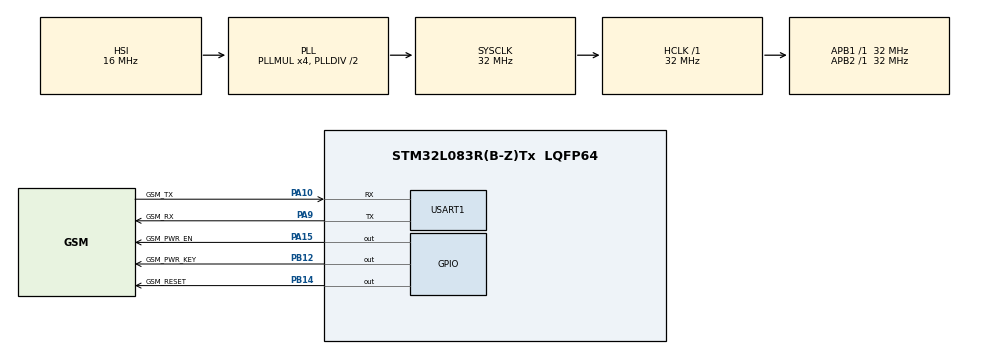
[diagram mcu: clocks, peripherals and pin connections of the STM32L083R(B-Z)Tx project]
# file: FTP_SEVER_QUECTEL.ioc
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Mcu.Family=STM32L0
Mcu.Name=STM32L083R(B-Z)Tx
Mcu.Package=LQFP64
NVIC.USART1_IRQn=true\:0\:0\:false\:false\:true\:true\:true
PA10.GPIO_Label=GSM_TX
PA10.Mode=Asynchronous
PA10.Signal=USART1_RX
PA13.Mode=Serial_Wire
PA13.Signal=SYS_SWDIO
PA14.Mode=Serial_Wire
PA14.Signal=SYS_SWCLK
PA15.GPIO_Label=GSM_PWR_EN
PA15.Signal=GPIO_Output
PA9.GPIO_Label=GSM_RX
PA9.Mode=Asynchronous
PA9.Signal=USART1_TX
PB12.GPIO_Label=GSM_PWR_KEY
PB12.Signal=GPIO_Output
PB14.GPIO_Label=GSM_RESET
PB14.Signal=GPIO_Output
ProjectManager.HeapSize=0x200
ProjectManager.StackSize=0x400
ProjectManager.TargetToolchain=MDK-ARM V5
RCC.AHBFreq_Value=32000000
RCC.APB1Freq_Value=32000000
RCC.APB1TimFreq_Value=32000000
RCC.APB2Freq_Value=32000000
RCC.APB2TimFreq_Value=32000000
RCC.HCLKFreq_Value=32000000
RCC.HSE_VALUE=8000000
RCC.HSI16_VALUE=16000000
RCC.HSI48_VALUE=48000000
RCC.HSI_VALUE=16000000
RCC.LSE_VALUE=32768
RCC.MSI_VALUE=2097000
RCC.PLLMUL=RCC_PLLMUL_4
RCC.SYSCLKFreq_VALUE=32000000
RCC.SYSCLKSource=RCC_SYSCLKSOURCE_PLLCLK
RCC.VCOOutputFreq_Value=64000000
USART1.VirtualMode-Asynchronous=VM_ASYNC
board=custom

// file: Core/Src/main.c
/* USER CODE BEGIN Header */
/**
  ******************************************************************************
  * @file           : main.c
  * @brief          : Main program body
  ******************************************************************************
  * @attention
  *
  * Copyright (c) 2022 STMicroelectronics.
  * All rights reserved.
  *
  * This software is licensed under terms that can be found in the LICENSE file
  * in the root directory of this software component.
  * If no LICENSE file comes with this software, it is provided AS-IS.
  *
  ******************************************************************************
  */
/* USER CODE END Header */
#include "main.h"

/* USER CODE BEGIN Includes */
#include "app_debug.h"
#include "ringBuffer.h"
#include "hw_polling_task.h"
#include "gsm_data_layer.h"
/* USER CODE END Includes */

UART_HandleTypeDef huart1;

void SystemClock_Config(void);
static void MX_GPIO_Init(void);
static void MX_USART1_UART_Init(void);
/* USER CODE BEGIN PFP */

void gsm_handler (void);

//void getDone (at_cmd_response_evt_t evt);   // du lieu nhan ve
/**************   main handle program  ******************/

/* USER CODE END PFP */

int main(void)
{

  /* MCU Configuration--------------------------------------------------------*/

  /* Reset of all peripherals, Initializes the Flash interface and the Systick. */
  HAL_Init();

  /* Configure the system clock */
  SystemClock_Config();

  /* Initialize all configured peripherals */
  MX_GPIO_Init();
  MX_USART1_UART_Init();
  /* USER CODE BEGIN 2 */
    HAL_Delay (300);
    ringBufferInit (&ringBuff, temp);        // seting for ring buffer
    USART1 ->CR1 |=   1 << 5;               /// RXEN ENABLE
  /* USER CODE END 2 */

  /* Infinite loop */
  /* USER CODE BEGIN WHILE */
  while (1)
  {
      gsm_handler();
    /* USER CODE END WHILE */

  }
}

void SystemClock_Config(void)
{
  RCC_OscInitTypeDef RCC_OscInitStruct = {0};
  RCC_ClkInitTypeDef RCC_ClkInitStruct = {0};
  RCC_PeriphCLKInitTypeDef PeriphClkInit = {0};

  /** Configure the main internal regulator output voltage
  */
  __HAL_PWR_VOLTAGESCALING_CONFIG(PWR_REGULATOR_VOLTAGE_SCALE1);
  /** Initializes the RCC Oscillators according to the specified parameters
  * in the RCC_OscInitTypeDef structure.
  */
  RCC_OscInitStruct.OscillatorType = RCC_OSCILLATORTYPE_HSI;
  RCC_OscInitStruct.HSIState = RCC_HSI_ON;
  RCC_OscInitStruct.HSICalibrationValue = RCC_HSICALIBRATION_DEFAULT;
  RCC_OscInitStruct.PLL.PLLState = RCC_PLL_ON;
  RCC_OscInitStruct.PLL.PLLSource = RCC_PLLSOURCE_HSI;
  RCC_OscInitStruct.PLL.PLLMUL = RCC_PLLMUL_4;
  RCC_OscInitStruct.PLL.PLLDIV = RCC_PLLDIV_2;
  if (HAL_RCC_OscConfig(&RCC_OscInitStruct) != HAL_OK)
  {
    Error_Handler();
  }
  /** Initializes the CPU, AHB and APB buses clocks
  */
  RCC_ClkInitStruct.ClockType = RCC_CLOCKTYPE_HCLK|RCC_CLOCKTYPE_SYSCLK
                              |RCC_CLOCKTYPE_PCLK1|RCC_CLOCKTYPE_PCLK2;
  RCC_ClkInitStruct.SYSCLKSource = RCC_SYSCLKSOURCE_PLLCLK;
  RCC_ClkInitStruct.AHBCLKDivider = RCC_SYSCLK_DIV1;
  RCC_ClkInitStruct.APB1CLKDivider = RCC_HCLK_DIV1;
  RCC_ClkInitStruct.APB2CLKDivider = RCC_HCLK_DIV1;

  if (HAL_RCC_ClockConfig(&RCC_ClkInitStruct, FLASH_LATENCY_1) != HAL_OK)
  {
    Error_Handler();
  }
  PeriphClkInit.PeriphClockSelection = RCC_PERIPHCLK_USART1;
  PeriphClkInit.Usart1ClockSelection = RCC_USART1CLKSOURCE_PCLK2;
  if (HAL_RCCEx_PeriphCLKConfig(&PeriphClkInit) != HAL_OK)
  {
    Error_Handler();
  }
}

static void MX_USART1_UART_Init(void)
{

  huart1.Instance = USART1;
  huart1.Init.BaudRate = 115200;
  huart1.Init.WordLength = UART_WORDLENGTH_8B;
  huart1.Init.StopBits = UART_STOPBITS_1;
  huart1.Init.Parity = UART_PARITY_NONE;
  huart1.Init.Mode = UART_MODE_TX_RX;
  huart1.Init.HwFlowCtl = UART_HWCONTROL_NONE;
  huart1.Init.OverSampling = UART_OVERSAMPLING_16;
  huart1.Init.OneBitSampling = UART_ONE_BIT_SAMPLE_DISABLE;
  huart1.AdvancedInit.AdvFeatureInit = UART_ADVFEATURE_NO_INIT;
  if (HAL_UART_Init(&huart1) != HAL_OK)
  {
    Error_Handler();
  }

}

static void MX_GPIO_Init(void)
{
  GPIO_InitTypeDef GPIO_InitStruct = {0};

  /* GPIO Ports Clock Enable */
  __HAL_RCC_GPIOB_CLK_ENABLE();
  __HAL_RCC_GPIOA_CLK_ENABLE();

  /*Configure GPIO pin Output Level */
  HAL_GPIO_WritePin(GPIOB, GSM_PWR_KEY_Pin|GSM_RESET_Pin, GPIO_PIN_RESET);

  /*Configure GPIO pin Output Level */
  HAL_GPIO_WritePin(GSM_PWR_EN_GPIO_Port, GSM_PWR_EN_Pin, GPIO_PIN_RESET);

  /*Configure GPIO pins : GSM_PWR_KEY_Pin GSM_RESET_Pin */
  GPIO_InitStruct.Pin = GSM_PWR_KEY_Pin|GSM_RESET_Pin;
  GPIO_InitStruct.Mode = GPIO_MODE_OUTPUT_PP;
  GPIO_InitStruct.Pull = GPIO_NOPULL;
  GPIO_InitStruct.Speed = GPIO_SPEED_FREQ_LOW;
  HAL_GPIO_Init(GPIOB, &GPIO_InitStruct);

  /*Configure GPIO pin : GSM_PWR_EN_Pin */
  GPIO_InitStruct.Pin = GSM_PWR_EN_Pin;
  GPIO_InitStruct.Mode = GPIO_MODE_OUTPUT_PP;
  GPIO_InitStruct.Pull = GPIO_NOPULL;
  GPIO_InitStruct.Speed = GPIO_SPEED_FREQ_LOW;
  HAL_GPIO_Init(GSM_PWR_EN_GPIO_Port, &GPIO_InitStruct);

}

/* USER CODE BEGIN 4 */
void gsm_handler (void)
{
    gsm_hw_polling_task();
    gm_state_machine_polling();

}
void RX1Callback(void)
{
    WriteToRingBuffer(&ringBuff, USART1);
}
/* USER CODE END 4 */

void Error_Handler(void)
{
  __disable_irq();
  while (1)
  {
  }
}
